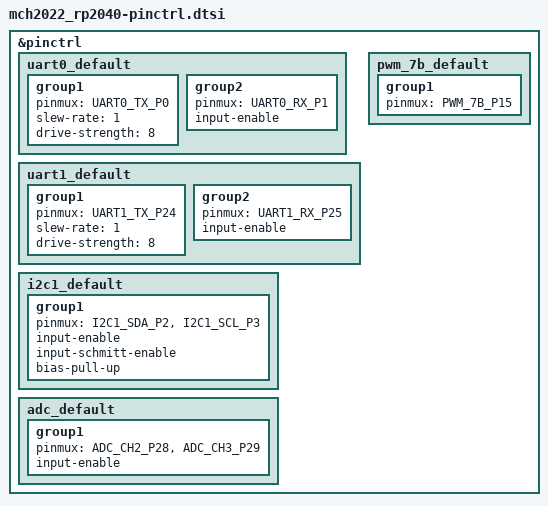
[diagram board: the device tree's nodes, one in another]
/*
 * SPDX-License-Identifier: GPL-3.0-or-later
 */

#include <zephyr/dt-bindings/pinctrl/rpi-pico-rp2040-pinctrl.h>

&pinctrl {
	/* To the ESP32: its console and the esp-sdr link, some Mbaud. */
	uart0_default: uart0_default {
		group1 {
			pinmux = <UART0_TX_P0>;
			slew-rate = <1>;
			drive-strength = <8>;
		};

		group2 {
			pinmux = <UART0_RX_P1>;
			input-enable;
		};
	};

	/* To the FPGA. */
	uart1_default: uart1_default {
		group1 {
			pinmux = <UART1_TX_P24>;
			slew-rate = <1>;
			drive-strength = <8>;
		};

		group2 {
			pinmux = <UART1_RX_P25>;
			input-enable;
		};
	};

	/* The system I2C bus, the ESP32 its controller. */
	i2c1_default: i2c1_default {
		group1 {
			pinmux = <I2C1_SDA_P2>, <I2C1_SCL_P3>;
			input-enable;
			input-schmitt-enable;
			bias-pull-up;
		};
	};

	/* The panel's backlight. */
	pwm_7b_default: pwm_7b_default {
		group1 {
			pinmux = <PWM_7B_P15>;
		};
	};

	/* VUSB and VBAT, each behind a 100k/100k divider. */
	adc_default: adc_default {
		group1 {
			pinmux = <ADC_CH2_P28>, <ADC_CH3_P29>;
			input-enable;
		};
	};
};
